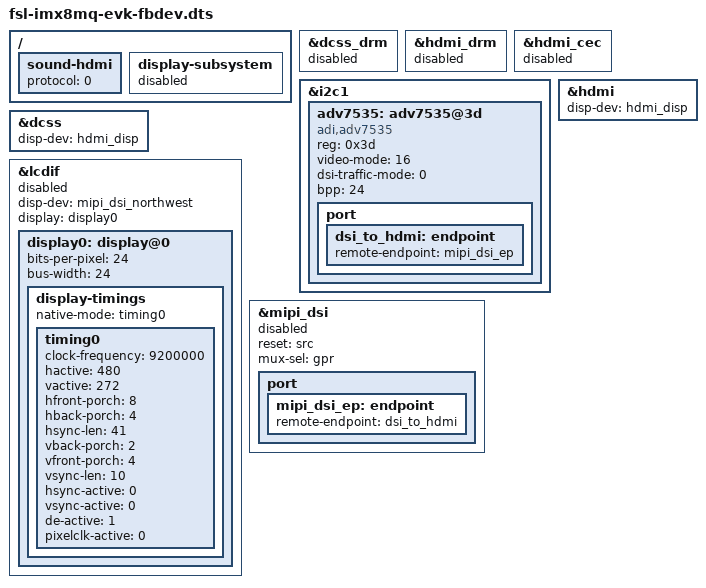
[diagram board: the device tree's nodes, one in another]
/*
 * Copyright (C) 2016 Freescale Semiconductor, Inc.
 * Copyright 2017 NXP
 *
 * This program is free software; you can redistribute it and/or
 * modify it under the terms of the GNU General Public License
 * as published by the Free Software Foundation; either version 2
 * of the License, or (at your option) any later version.
 *
 * This program is distributed in the hope that it will be useful,
 * but WITHOUT ANY WARRANTY; without even the implied warranty of
 * MERCHANTABILITY or FITNESS FOR A PARTICULAR PURPOSE.  See the
 * GNU General Public License for more details.
 */

#include "fsl-imx8mq-evk.dts"

/ {
	sound-hdmi {
		protocol = <0>;
	};

	display-subsystem {
		status = "disabled";
	};
};

&dcss_drm {
	status = "disabled";
};

&hdmi_drm {
	status = "disabled";
};

&hdmi_cec {
	status = "disabled";
};

&i2c1 {
	adv7535: adv7535@3d {
		compatible = "adi,adv7535";
		reg = <0x3d>;		/* PD pin is low */
		/* TODO: pin config & irq */
		video-mode = <16>;	/* 1920x1080@60HZ */
		dsi-traffic-mode = <0>;
		bpp = <24>;
		status = "okay";
		port {
			dsi_to_hdmi: endpoint {
				remote-endpoint = <&mipi_dsi_ep>;
			};
		};
	};
};

&hdmi {
	disp-dev = "hdmi_disp";
	status = "okay";
};

&dcss {
	disp-dev = "hdmi_disp";
	status = "okay";
};

&lcdif {
	status = "disabled";
	disp-dev = "mipi_dsi_northwest";
	display = <&display0>;

	display0: display@0 {
		bits-per-pixel = <24>;
		bus-width = <24>;

		display-timings {
			native-mode = <&timing0>;
			timing0: timing0 {
			clock-frequency = <9200000>;
			hactive = <480>;
			vactive = <272>;
			hfront-porch = <8>;
			hback-porch = <4>;
			hsync-len = <41>;
			vback-porch = <2>;
			vfront-porch = <4>;
			vsync-len = <10>;

			hsync-active = <0>;
			vsync-active = <0>;
			de-active = <1>;
			pixelclk-active = <0>;
			};
		};
	};
};

&mipi_dsi {
	reset = <&src>;
	mux-sel = <&gpr>;	/* lcdif or dcss */
	status = "disabled";
	port {
		mipi_dsi_ep: endpoint {
			remote-endpoint = <&dsi_to_hdmi>;
		};
	};
};
